# ATmega162 device description
Architecture: AVR8; Family: megaAVR
Registers are 8-bit, access not given, no defined reset value unless marked. A register's access mark holds for its fields unless they carry their own. Offsets are from the block's base; [hi:lo] are bit positions; 'fields as' and 'values as' point back to an identical list.

## SPI — Serial Peripheral Interface
Instances: SPI 0x00
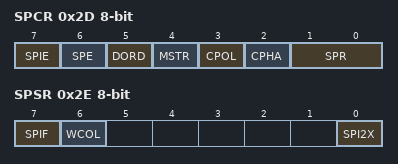
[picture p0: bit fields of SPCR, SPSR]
0x2D SPCR — SPI Control Register
  [7] SPIE — SPI Interrupt Enable
  [6] SPE — SPI Enable
  [5] DORD — Data Order
  [4] MSTR — Master/Slave Select
  [3] CPOL — Clock polarity
  [2] CPHA — Clock Phase
  [1:0] SPR — SPI Clock Rate Selects
    0=FOSC_4; 1=FOSC_16; 2=FOSC_64; 3=FOSC_128; 4=FOSC_2; 5=FOSC_8; 6=FOSC_32; 7=FOSC_64
0x2E SPSR — SPI Status Register
  [7] SPIF — SPI Interrupt Flag
  [6] WCOL — Write Collision Flag
  [0] SPI2X — Double SPI Speed Bit
0x2F SPDR — SPI Data Register

## CPU — CPU Registers
Instances: CPU 0x00
0x24 OSCCAL — Oscillator Calibration Value
  [7:0] OSCCAL — Oscillator Calibration
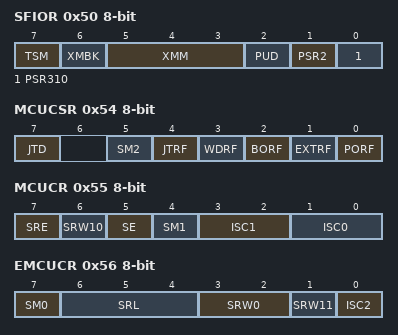
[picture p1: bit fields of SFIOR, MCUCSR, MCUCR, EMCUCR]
0x50 SFIOR — Special Function IO Register
  [7] TSM — Timer/Counter Synchronization Mode
  [6] XMBK — External Memory Bus Keeper Enable
  [5:3] XMM — External Memory High Mask Bits
  [2] PUD — Pull-up Disable
  [1] PSR2 — Prescaler Reset Timer/Counter2
  [0] PSR310 — Prescaler Reset Timer/Counter3, Timer/Counter1 and Timer/Counter0
0x54 MCUCSR — MCU Control And Status Register
  [7] JTD — JTAG Interface Disable
  [5] SM2 — Sleep Mode Select Bit 2
  [4] JTRF — JTAG Reset Flag
  [3] WDRF — Watchdog Reset Flag
  [2] BORF — Brown-out Reset Flag
  [1] EXTRF — External Reset Flag
  [0] PORF — Power-on reset flag
0x55 MCUCR — MCU Control Register
  [7] SRE — External SRAM Enable
  [6] SRW10 — External SRAM Wait State Select
  [5] SE — Sleep Enable
  [4] SM1 — Sleep Mode Select
  [3:2] ISC1 — Interrupt Sense Control 1 bits
    0=LOW_LEVEL_OF_INTX; 1=ANY_LOGICAL_CHANGE_IN_INTX; 2=FALLING_EDGE_OF_INTX; 3=RISING_EDGE_OF_INTX
  [1:0] ISC0 — Interrupt Sense Control 0 bits
    values as ISC1
0x56 EMCUCR — Extended MCU Control Register
  [7] SM0 — Sleep mode Select Bit 0
  [6:4] SRL — Wait State Sector Limit Bits
    0=LS_N_A_US_0X1100_0XFFFF; 1=LS_0X1100_0X1FFF_US_0X2000_0XFFFF; 2=LS_0X1100_0X3FFF_US_0X4000_0XFFFF; 3=LS_0X1100_0X5FFF_US_0X6000_0XFFFF; 4=LS_0X1100_0X7FFF_US_0X8000_0XFFFF; 5=LS_0X1100_0X9FFF_US_0XA000_0XFFFF; 6=LS_0X1100_0XBFFF_US_0XC000_0XFFFF; 7=LS_0X1100_0XDFFF_US_0XE000_0XFFFF
  [3:2] SRW0 — Wait State Select Bit 1 for Lower Sector
    0=NO_WAIT_STATES; 1=WAIT_ONE_CYCLE_DURING_READ_WRITE_STROBE; 2=WAIT_TWO_CYCLES_DURING_READ_WRITE_STROBE; 3=WAIT_TWO_CYCLES_DURING_READ_WRITE_AND_WAIT_ONE_CYCLE_BEFORE_DRIVING_OUT_NEW_ADDRESS
  [1] SRW11 — Wait State Select Bit 1 for Upper Sector
  [0] ISC2 — Interrupt Sense Control 2
0x5D SP 16-bit — Stack Pointer
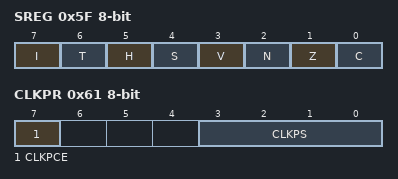
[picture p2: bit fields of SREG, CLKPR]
0x5F SREG — Status Register
  [7] I — Global Interrupt Enable
  [6] T — Bit Copy Storage
  [5] H — Half Carry Flag
  [4] S — Sign Bit
  [3] V — Two's Complement Overflow Flag
  [2] N — Negative Flag
  [1] Z — Zero Flag
  [0] C — Carry Flag
0x61 CLKPR — Clock prescale register
  [7] CLKPCE — Clock Prescaler Change Enable
  [3:0] CLKPS — Clock Prescaler Select Bits
    0=1; 1=2; 2=4; 3=8; 4=16; 5=32; 6=64; 7=128; 8=256
Value list OSCCAL_VALUE_ADDRESSES: 0=8_0_MHz

## JTAG — JTAG Interface
Instances: JTAG 0x00
0x24 OCDR — On-Chip Debug Related Register in I/O Memory
  [7:0] OCDR — On-Chip Debug Register Bits
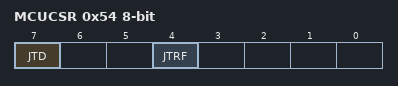
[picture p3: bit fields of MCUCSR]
0x54 MCUCSR — MCU Control And Status Register
  [7] JTD — JTAG Interface Disable
  [4] JTRF — JTAG Reset Flag

## BOOT_LOAD — Bootloader
Instances: BOOT_LOAD 0x00
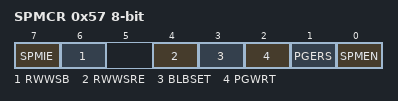
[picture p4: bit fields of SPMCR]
0x57 SPMCR — Store Program Memory Control Register
  [7] SPMIE — SPM Interrupt Enable
  [6] RWWSB — Read While Write Section Busy
  [4] RWWSRE — Read While Write section read enable
  [3] BLBSET — Boot Lock Bit Set
  [2] PGWRT — Page Write
  [1] PGERS — Page Erase
  [0] SPMEN — Store Program Memory Enable

## EEPROM
Instances: EEPROM 0x00
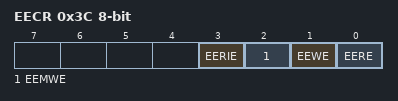
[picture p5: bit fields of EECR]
0x3C EECR — EEPROM Control Register
  [3] EERIE — EEPROM Ready Interrupt Enable
  [2] EEMWE — EEPROM Master Write Enable
  [1] EEWE — EEPROM Write Enable
  [0] EERE — EEPROM Read Enable
0x3D EEDR — EEPROM Data Register
  [7:0] EEDR — EEPROM Data Register bits
0x3E EEAR 16-bit — EEPROM Address Register Bytes
  [8:0] EEAR — EEPROM Address Register bits

## PORTA — I/O Port
Instances: PORTA 0x00
0x39 PINA — Port A Input Pins
0x3A DDRA — Port A Data Direction Register
0x3B PORTA — Port A Data Register

## PORTB — I/O Port
Instances: PORTB 0x00
0x36 PINB — Port B Input Pins
0x37 DDRB — Port B Data Direction Register
0x38 PORTB — Port B Data Register

## PORTC — I/O Port
Instances: PORTC 0x00
0x33 PINC — Port C Input Pins
0x34 DDRC — Port C Data Direction Register
0x35 PORTC — Port C Data Register

## PORTD — I/O Port
Instances: PORTD 0x00
0x30 PIND — Port D Input Pins
0x31 DDRD — Port D Data Direction Register
0x32 PORTD — Port D Data Register

## PORTE — I/O Port
Instances: PORTE 0x00
0x25 PINE bits used 3:0 — Input Pins, Port E
0x26 DDRE bits used 2:0 — Data Direction Register, Port E
0x27 PORTE bits used 2:0 — Data Register, Port E

## TC0 (TC8 module) — Timer/Counter, 8-bit
Instances: TC0 0x00
0x51 OCR0 — Timer/Counter 0 Output Compare Register
0x52 TCNT0 — Timer/Counter 0 Register
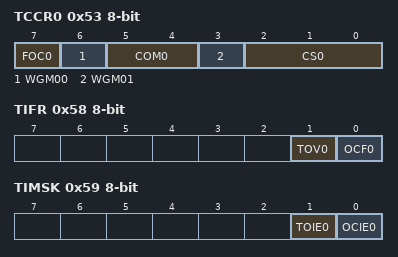
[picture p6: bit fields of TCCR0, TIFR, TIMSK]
0x53 TCCR0 — Timer/Counter 0 Control Register
  [7] FOC0 — Force Output Compare
  [6] WGM00 — Waveform Generation Mode 0
    0=NORMAL; 2=PWM_PHASE_CORRECT; 1=CTC; 3=FAST_PWM
  [5:4] COM0 — Compare Match Output Modes
  [3] WGM01 — Waveform Generation Mode 1
  [2:0] CS0 — Clock Selects
    0=NO_CLOCK_SOURCE_STOPPED; 1=RUNNING_NO_PRESCALING; 2=RUNNING_CLK_8; 3=RUNNING_CLK_64; 4=RUNNING_CLK_256; 5=RUNNING_CLK_1024; 6=RUNNING_EXTCLK_TN_FALLING_EDGE; 7=RUNNING_EXTCLK_TN_RISING_EDGE
0x58 TIFR — Timer/Counter Interrupt Flag register
  [1] TOV0 — Timer/Counter0 Overflow Flag
  [0] OCF0 — Output Compare Flag 0
0x59 TIMSK — Timer/Counter Interrupt Mask Register
  [1] TOIE0 — Timer/Counter0 Overflow Interrupt Enable
  [0] OCIE0 — Timer/Counter0 Output Compare Match Interrupt register

## WDT — Watchdog Timer
Instances: WDT 0x00
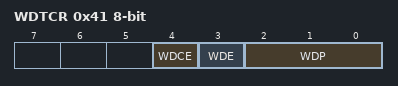
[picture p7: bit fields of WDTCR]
0x41 WDTCR — Watchdog Timer Control Register
  [4] WDCE — Watchdog Change Enable
  [3] WDE — Watch Dog Enable
  [2:0] WDP — Watch Dog Timer Prescaler bits
    0=OSCILLATOR_CYCLES_16K; 1=OSCILLATOR_CYCLES_32K; 2=OSCILLATOR_CYCLES_64K; 3=OSCILLATOR_CYCLES_128K; 4=OSCILLATOR_CYCLES_256K; 5=OSCILLATOR_CYCLES_512K; 6=OSCILLATOR_CYCLES_1024K; 7=OSCILLATOR_CYCLES_2048K

## EXINT — External Interrupts
Instances: EXINT 0x00
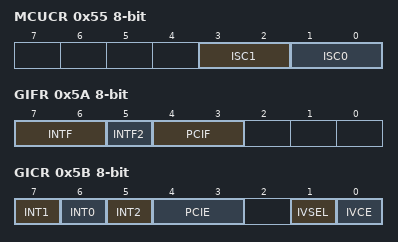
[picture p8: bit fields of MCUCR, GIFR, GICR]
0x55 MCUCR — MCU Control Register
  [3:2] ISC1 — Interrupt Sense Control 1 Bits
    0=LOW_LEVEL_OF_INTX; 1=ANY_LOGICAL_CHANGE_OF_INTX; 2=FALLING_EDGE_OF_INTX; 3=RISING_EDGE_OF_INTX
  [1:0] ISC0 — Interrupt Sense Control 0 Bits
    values as ISC1
0x56 EMCUCR — Extended MCU Control Register
  [0] ISC2 — Interrupt Sense Control 2
0x5A GIFR — General Interrupt Flag Register
  [7:6] INTF — External Interrupt Flags
  [5] INTF2 — External Interrupt Flag 2
  [4:3] PCIF — Pin Change Interrupt Flags
0x5B GICR — General Interrupt Control Register
  [7] INT1 — External Interrupt Request 1 Enable
  [6] INT0 — External Interrupt Request 0 Enable
  [5] INT2 — External Interrupt Request 2 Enable
  [4:3] PCIE — Pin Change Interrupt Enables
  [1] IVSEL — Interrupt Vector Select
  [0] IVCE — Interrupt Vector Change Enable
0x6B PCMSK0 — Pin Change Enable Mask
  [7:0] PCINT — Pin Change Interrupt mask bits
0x6C PCMSK1 — Pin Change Mask Register 1
  [7:0] PCINT (bit 8 of the value upward) — Pin Change Interrupt mask bits
